# PIC32CM2532JH01100 register map
Vendor: Microchip Technology; Series: PIC32CMJH01; File version: 0
CPU: CM0+ r0p0, selectable endian, MPU, no FPU, VTOR, 2 interrupt priority bits
Registers are 32-bit, read-write, reset 0x0 unless marked. A register's access mark holds for its fields unless they carry their own. Offsets are from the block's base; [hi:lo] are bit positions; {n}, {i} and the like mark numbered series.

## ICM — Integrity Check Monitor
Base 0x42006400; register names take the prefix ICM_
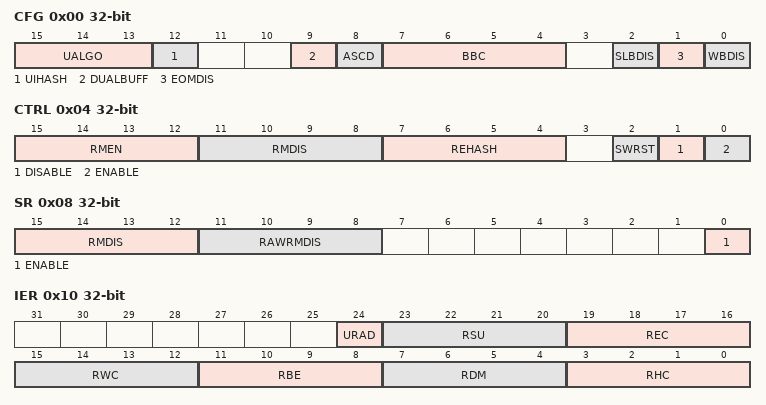
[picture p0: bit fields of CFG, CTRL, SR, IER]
0x00 CFG — Configuration
  [15:13] UALGO — User SHA Algorithm
    0=SHA1 (SHA1 Algorithm); 1=SHA256 (SHA256 Algorithm); 4=SHA224 (SHA224 Algorithm)
  [12] UIHASH — User Initial Hash Value
  [9] DUALBUFF — Dual Input Buffer
  [8] ASCD — Automatic Switch To Compare Digest
  [7:4] BBC — Bus Burden Control
  [2] SLBDIS — Secondary List Branching Disable
  [1] EOMDIS — End of Monitoring Disable
  [0] WBDIS — Write Back Disable
0x04 CTRL wo — Control
  [15:12] RMEN — Region Monitoring Enable
  [11:8] RMDIS — Region Monitoring Disable
  [7:4] REHASH — Recompute Internal Hash
  [2] SWRST — Software Reset
  [1] DISABLE — ICM Disable Register
  [0] ENABLE — ICM Enable
0x08 SR ro — Status
  [15:12] RMDIS — Region Monitoring Disabled Status
  [11:8] RAWRMDIS — RAW Region Monitoring Disabled Status
  [0] ENABLE — ICM Controller Enable Register
0x10 IER wo — Interrupt Enable
  [24] URAD — Undefined Register Access Detection Interrupt Enable
  [23:20] RSU — Region Status Updated Interrupt Disable
  [19:16] REC — Region End bit Condition Detected Interrupt Enable
  [15:12] RWC — Region Wrap Condition detected Interrupt Enable
  [11:8] RBE — Region Bus Error Interrupt Enable
  [7:4] RDM — Region Digest Mismatch Interrupt Enable
  [3:0] RHC — Region Hash Completed Interrupt Enable
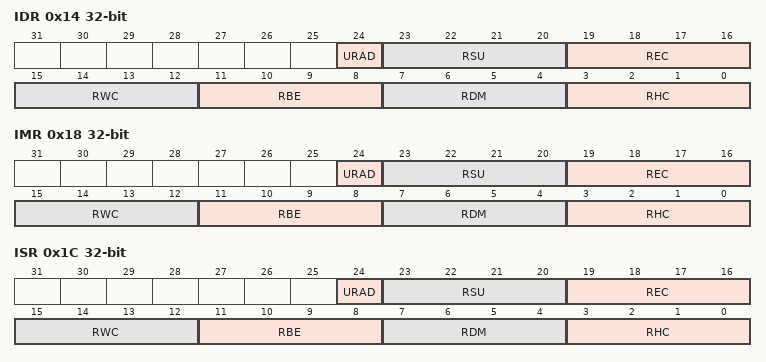
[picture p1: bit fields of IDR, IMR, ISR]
0x14 IDR wo — Interrupt Disable
  [24] URAD — Undefined Register Access Detection Interrupt Disable
  [23:20] RSU — Region Status Updated Interrupt Disable
  [19:16] REC — Region End bit Condition detected Interrupt Disable
  [15:12] RWC — Region Wrap Condition Detected Interrupt Disable
  [11:8] RBE — Region Bus Error Interrupt Disable
  [7:4] RDM — Region Digest Mismatch Interrupt Disable
  [3:0] RHC — Region Hash Completed Interrupt Disable
0x18 IMR ro — Interrupt Mask
  [24] URAD — Undefined Register Access Detection Interrupt Mask
  [23:20] RSU — Region Status Updated Interrupt Mask
  [19:16] REC — Region End bit Condition Detected Interrupt Mask
  [15:12] RWC — Region Wrap Condition Detected Interrupt Mask
  [11:8] RBE — Region Bus Error Interrupt Mask
  [7:4] RDM — Region Digest Mismatch Interrupt Mask
  [3:0] RHC — Region Hash Completed Interrupt Mask
0x1C ISR ro — Interrupt Status
  [24] URAD — Undefined Register Access Detection Status
  [23:20] RSU — Region Status Updated Detected
  [19:16] REC — Region End bit Condition Detected
  [15:12] RWC — Region Wrap Condition Detected
  [11:8] RBE — Region Bus Error
  [7:4] RDM — Region Digest Mismatch
  [3:0] RHC — Region Hash Completed
0x20 UASR ro — Undefined Access Status
  [2:0] URAT — Undefined Register Access Trace
    0=UNSPEC_STRUCT_MEMBER (Unspecified structure member set to one detected when the descriptor is loaded); 1=CFG_MODIFIED (CFG modified during active monitoring); 2=DSCR_MODIFIED (DSCR modified during active monitoring); 3=HASH_MODIFIED (HASH modified during active monitoring); 4=READ_ACCESS (Write-only register read access)
0x30 DSCR — Region Descriptor Area Start Address
  [31:6] DASA — Descriptor Area Start Address
0x34 HASH — Region Hash Area Start Address
  [31:7] HASA — Hash Area Start Address
{0x38+4i} UIHVAL[{i}] (i=0..7) wo — User Initial Hash Value n
  [31:0] VAL — Initial Hash Value

## SMBIST — SRAM MBIST Interface
Base 0x42006C00; register names take the prefix SMBIST_
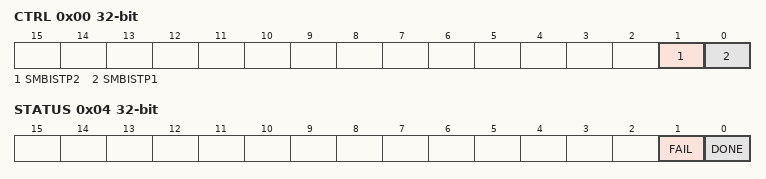
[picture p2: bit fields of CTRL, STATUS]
0x00 CTRL — Control
  [1] SMBISTP2 — SRAM MBIST Partition 2 test start
  [0] SMBISTP1 — SRAM MBIST Partition 1 test start
0x04 STATUS
  [1] FAIL, [0] DONE

## MCLK — Main Clock
Base 0x40000800; register names take the prefix MCLK_
0x01 INTENCLR 8-bit — Interrupt Enable Clear
  [0] CKRDY — Clock Ready Interrupt Enable
0x02 INTENSET 8-bit — Interrupt Enable Set
  [0] CKRDY — Clock Ready Interrupt Enable
0x03 INTFLAG 8-bit reset 0x1 — Interrupt Flag Status and Clear
  [0] CKRDY — Clock Ready
0x04 CPUDIV 8-bit reset 0x1 — CPU Clock Division
  [7:0] CPUDIV — CPU Clock Division Factor
    1=DIV1 (Divide by 1); 2=DIV2 (Divide by 2); 4=DIV4 (Divide by 4); 8=DIV8 (Divide by 8); 16=DIV16 (Divide by 16); 32=DIV32 (Divide by 32); 64=DIV64 (Divide by 64); 128=DIV128 (Divide by 128)
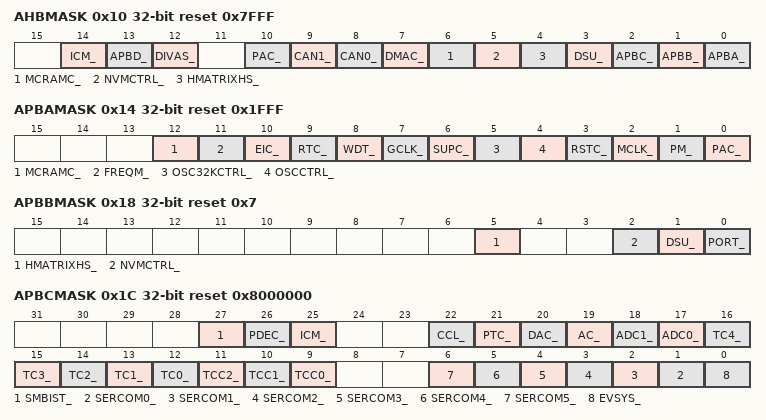
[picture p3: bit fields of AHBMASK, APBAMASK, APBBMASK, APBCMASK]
0x10 AHBMASK reset 0x7FFF
  [14] ICM_ — ICM AHB Clock Mask
  [13] APBD_ — APBD AHB Clock Mask
  [12] DIVAS_ — DIVAS AHB Clock Mask
  [10] PAC_ — PAC AHB Clock Mask
  [9] CAN1_ — CAN1 AHB Clock Mask
  [8] CAN0_ — CAN0 AHB Clock Mask
  [7] DMAC_ — DMAC AHB Clock Mask
  [6] MCRAMC_ — MCRAMC AHB Clock Mask
  [5] NVMCTRL_ — NVMCTRL AHB Clock Mask
  [4] HMATRIXHS_ — HMATRIXHS AHB Clock Mask
  [3] DSU_ — DSU AHB Clock Mask
  [2] APBC_ — APBC AHB Clock Mask
  [1] APBB_ — APBB AHB Clock Mask
  [0] APBA_ — APBA AHB Clock Mask
0x14 APBAMASK reset 0x1FFF
  [12] MCRAMC_ — MCRAMC APB Clock Enable
  [11] FREQM_ — FREQM APB Clock Enable
  [10] EIC_ — EIC APB Clock Enable
  [9] RTC_ — RTC APB Clock Enable
  [8] WDT_ — WDT APB Clock Enable
  [7] GCLK_ — GCLK APB Clock Enable
  [6] SUPC_ — SUPC APB Clock Enable
  [5] OSC32KCTRL_ — OSC32KCTRL APB Clock Enable
  [4] OSCCTRL_ — OSCCTRL APB Clock Enable
  [3] RSTC_ — RSTC APB Clock Enable
  [2] MCLK_ — MCLK APB Clock Enable
  [1] PM_ — PM APB Clock Enable
  [0] PAC_ — PAC APB Clock Enable
0x18 APBBMASK reset 0x7
  [5] HMATRIXHS_ — HMATRIXHS APB Clock Enable
  [2] NVMCTRL_ — NVMCTRL APB Clock Enable
  [1] DSU_ — DSU APB Clock Enable
  [0] PORT_ — PORT APB Clock Enable
0x1C APBCMASK reset 0x8000000
  [27] SMBIST_ — SMBIST APB Clock Enable
  [26] PDEC_ — PDEC APB Clock Enable
  [25] ICM_ — ICM APB Clock Enable
  [22] CCL_ — CCL APB Clock Enable
  [21] PTC_ — PTC APB Clock Enable
  [20] DAC_ — DAC APB Clock Enable
  [19] AC_ — AC APB Clock Enable
  [18] ADC1_ — ADC1 APB Clock Enable
  [17] ADC0_ — ADC0 APB Clock Enable
  [n+12] TC{n}_ (n=0..4) — TC{n} APB Clock Enable
  [11] TCC2_ — TCC2 APB Clock Enable
  [10] TCC1_ — TCC1 APB Clock Enable
  [9] TCC0_ — TCC0 APB Clock Enable
  [n+1] SERCOM{n}_ (n=0..5) — SERCOM{n} APB Clock Enable
  [0] EVSYS_ — EVSYS APB Clock Enable
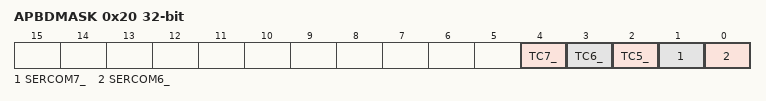
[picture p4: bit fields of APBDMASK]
0x20 APBDMASK
  [4] TC7_ — TC7 APB Clock Enable
  [3] TC6_ — TC6 APB Clock Enable
  [2] TC5_ — TC5 APB Clock Enable
  [1] SERCOM7_ — SERCOM7 APB Clock Enable
  [0] SERCOM6_ — SERCOM6 APB Clock Enable

## Notices in the file
Copyright (c) 2017 Microchip Technology Inc.
SPDX-License-Identifier: Apache-2.0
Licensed under the Apache License, Version 2.0 (the "License");
you may not use this file except in compliance with the License.
You may obtain a copy of the License at
http://www.apache.org/licenses/LICENSE-2.0
Unless required by applicable law or agreed to in writing, software
distributed under the License is distributed on an "AS IS" BASIS,
WITHOUT WARRANTIES OR CONDITIONS OF ANY KIND, either express or implied.
See the License for the specific language governing permissions and
limitations under the License.
